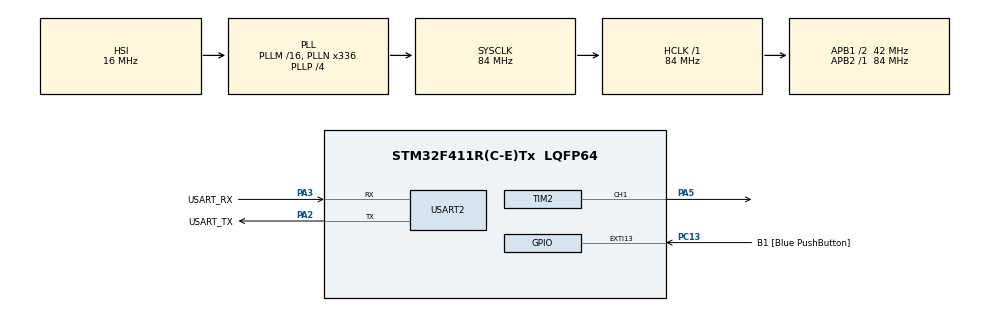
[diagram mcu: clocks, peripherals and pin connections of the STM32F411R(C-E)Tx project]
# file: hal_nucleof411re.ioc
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Mcu.Family=STM32F4
Mcu.Name=STM32F411R(C-E)Tx
Mcu.Package=LQFP64
NVIC.PriorityGroup=NVIC_PRIORITYGROUP_0
NVIC.TIM3_IRQn=true\:0\:0\:false\:false\:true\:true\:true
NVIC.TIM4_IRQn=true\:0\:0\:false\:false\:true\:true\:true
PA13.GPIO_Label=TMS
PA13.Mode=Serial_Wire
PA13.Signal=SYS_JTMS-SWDIO
PA14.GPIO_Label=TCK
PA14.Mode=Serial_Wire
PA14.Signal=SYS_JTCK-SWCLK
PA2.GPIO_Label=USART_TX
PA2.Mode=Asynchronous
PA2.Signal=USART2_TX
PA3.GPIO_Label=USART_RX
PA3.Mode=Asynchronous
PA3.Signal=USART2_RX
PA5.Signal=S_TIM2_CH1_ETR
PB3.GPIO_Label=SWO
PB3.Signal=SYS_JTDO-SWO
PC13-ANTI_TAMP.GPIO_Label=B1 [Blue PushButton]
PC13-ANTI_TAMP.GPIO_ModeDefaultEXTI=GPIO_MODE_IT_FALLING
PC13-ANTI_TAMP.Signal=GPXTI13
PC14-OSC32_IN.Mode=LSE-External-Oscillator
PC14-OSC32_IN.Signal=RCC_OSC32_IN
PC15-OSC32_OUT.Mode=LSE-External-Oscillator
PC15-OSC32_OUT.Signal=RCC_OSC32_OUT
PH0\ -\ OSC_IN.Mode=HSE-External-Clock-Source
PH0\ -\ OSC_IN.Signal=RCC_OSC_IN
PH1\ -\ OSC_OUT.Mode=HSE-External-Clock-Source
PH1\ -\ OSC_OUT.Signal=RCC_OSC_OUT
ProjectManager.HeapSize=0x200
ProjectManager.StackSize=0x400
ProjectManager.TargetToolchain=SW4STM32
RCC.48MHZClocksFreq_Value=84000000
RCC.AHBFreq_Value=84000000
RCC.APB1CLKDivider=RCC_HCLK_DIV2
RCC.APB1Freq_Value=42000000
RCC.APB1TimFreq_Value=84000000
RCC.APB2Freq_Value=84000000
RCC.APB2TimFreq_Value=84000000
RCC.CortexFreq_Value=84000000
RCC.FLatency-AdvancedSettings=FLASH_LATENCY_2
RCC.HCLKFreq_Value=84000000
RCC.HSE_VALUE=8000000
RCC.HSI_VALUE=16000000
RCC.PLLN=336
RCC.PLLP=RCC_PLLP_DIV4
RCC.SYSCLKFreq_VALUE=84000000
RCC.SYSCLKSource=RCC_SYSCLKSOURCE_PLLCLK
RCC.VCOOutputFreq_Value=336000000
SH.S_TIM2_CH1_ETR.0=TIM2_CH1,PWM Generation1 CH1
TIM2.Channel-PWM\ Generation1\ CH1=TIM_CHANNEL_1
TIM2.Period=999
TIM2.Prescaler=3
TIM3.AutoReloadPreload=TIM_AUTORELOAD_PRELOAD_ENABLE
TIM3.Period=(2333-1)/500
TIM3.Prescaler=36000-1
TIM3.TIM_MasterOutputTrigger=TIM_TRGO_UPDATE
TIM4.AutoReloadPreload=TIM_AUTORELOAD_PRELOAD_ENABLE
TIM4.Period=(2333-1)/500
TIM4.Prescaler=36000-1
TIM4.TIM_MasterOutputTrigger=TIM_TRGO_UPDATE
USART2.VirtualMode=VM_ASYNC
VP_TIM2_VS_ClockSourceINT.Mode=Internal
VP_TIM3_VS_ClockSourceINT.Mode=Internal
VP_TIM4_VS_ClockSourceINT.Mode=Internal
board=NUCLEO-F411RE

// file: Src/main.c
/* USER CODE BEGIN Header */
/**
  ******************************************************************************
  * @file           : main.c
  * @brief          : Main program body
  ******************************************************************************
  * @attention
  *
  * <h2><center>&copy; Copyright (c) 2019 STMicroelectronics.
  * All rights reserved.</center></h2>
  *
  * This software component is licensed by ST under BSD 3-Clause license,
  * the "License"; You may not use this file except in compliance with the
  * License. You may obtain a copy of the License at:
  *                        opensource.org/licenses/BSD-3-Clause
  *
  ******************************************************************************
  */
/* USER CODE END Header */

#include "main.h"

/* USER CODE BEGIN Includes */
#include "core.hpp"
/* USER CODE END Includes */

TIM_HandleTypeDef htim2;
TIM_HandleTypeDef htim3;
TIM_HandleTypeDef htim4;

UART_HandleTypeDef huart2;

/* USER CODE BEGIN PV */
#ifdef __GNUC__
#define PUTCHAR_PROTOTYPE int __io_putchar(int ch)
#else
#define PUTCHAR_PROTOTYPE int fputc(int ch, FILE *f)
#endif /* __GNUC__ */

void __io_putchar(uint8_t ch) {
    HAL_UART_Transmit(&huart2, &ch, 1, 1);
}
/* USER CODE END PV */

void SystemClock_Config(void);

static void MX_GPIO_Init(void);

static void MX_USART2_UART_Init(void);

static void MX_TIM4_Init(void);

static void MX_TIM3_Init(void);

static void MX_TIM2_Init(void);

int main(void) {

    /* MCU Configuration--------------------------------------------------------*/

    /* Reset of all peripherals, Initializes the Flash interface and the Systick. */
    HAL_Init();

    /* Configure the system clock */
    SystemClock_Config();

    /* Initialize all configured peripherals */
    MX_GPIO_Init();
    MX_USART2_UART_Init();
    MX_TIM4_Init();
    MX_TIM3_Init();
    MX_TIM2_Init();
    /* USER CODE BEGIN 2 */
    HAL_TIM_Base_Start_IT(&htim3);
    HAL_TIM_Base_Start_IT(&htim4);
    HAL_TIM_PWM_Start(&htim2, TIM_CHANNEL_1);
    /* USER CODE END 2 */

    /* Infinite loop */
    /* USER CODE BEGIN WHILE */
    Initialize(&htim2);
    Core();

    while (1) {
        /* USER CODE END WHILE */

    }
}

void SystemClock_Config(void) {
    RCC_OscInitTypeDef RCC_OscInitStruct = {0};
    RCC_ClkInitTypeDef RCC_ClkInitStruct = {0};

    /** Configure the main internal regulator output voltage
    */
    __HAL_RCC_PWR_CLK_ENABLE();
    __HAL_PWR_VOLTAGESCALING_CONFIG(PWR_REGULATOR_VOLTAGE_SCALE1);
    /** Initializes the CPU, AHB and APB busses clocks
    */
    RCC_OscInitStruct.OscillatorType = RCC_OSCILLATORTYPE_HSI;
    RCC_OscInitStruct.HSIState = RCC_HSI_ON;
    RCC_OscInitStruct.HSICalibrationValue = RCC_HSICALIBRATION_DEFAULT;
    RCC_OscInitStruct.PLL.PLLState = RCC_PLL_ON;
    RCC_OscInitStruct.PLL.PLLSource = RCC_PLLSOURCE_HSI;
    RCC_OscInitStruct.PLL.PLLM = 16;
    RCC_OscInitStruct.PLL.PLLN = 336;
    RCC_OscInitStruct.PLL.PLLP = RCC_PLLP_DIV4;
    RCC_OscInitStruct.PLL.PLLQ = 4;
    if (HAL_RCC_OscConfig(&RCC_OscInitStruct) != HAL_OK) {
        Error_Handler();
    }
    /** Initializes the CPU, AHB and APB busses clocks
    */
    RCC_ClkInitStruct.ClockType = RCC_CLOCKTYPE_HCLK | RCC_CLOCKTYPE_SYSCLK
                                  | RCC_CLOCKTYPE_PCLK1 | RCC_CLOCKTYPE_PCLK2;
    RCC_ClkInitStruct.SYSCLKSource = RCC_SYSCLKSOURCE_PLLCLK;
    RCC_ClkInitStruct.AHBCLKDivider = RCC_SYSCLK_DIV1;
    RCC_ClkInitStruct.APB1CLKDivider = RCC_HCLK_DIV2;
    RCC_ClkInitStruct.APB2CLKDivider = RCC_HCLK_DIV1;

    if (HAL_RCC_ClockConfig(&RCC_ClkInitStruct, FLASH_LATENCY_2) != HAL_OK) {
        Error_Handler();
    }
}

static void MX_TIM2_Init(void) {

    TIM_ClockConfigTypeDef sClockSourceConfig = {0};
    TIM_MasterConfigTypeDef sMasterConfig = {0};
    TIM_OC_InitTypeDef sConfigOC = {0};

    htim2.Instance = TIM2;
    htim2.Init.Prescaler = 3;
    htim2.Init.CounterMode = TIM_COUNTERMODE_UP;
    htim2.Init.Period = 999;
    htim2.Init.ClockDivision = TIM_CLOCKDIVISION_DIV1;
    htim2.Init.AutoReloadPreload = TIM_AUTORELOAD_PRELOAD_DISABLE;
    if (HAL_TIM_Base_Init(&htim2) != HAL_OK) {
        Error_Handler();
    }
    sClockSourceConfig.ClockSource = TIM_CLOCKSOURCE_INTERNAL;
    if (HAL_TIM_ConfigClockSource(&htim2, &sClockSourceConfig) != HAL_OK) {
        Error_Handler();
    }
    if (HAL_TIM_PWM_Init(&htim2) != HAL_OK) {
        Error_Handler();
    }
    sMasterConfig.MasterOutputTrigger = TIM_TRGO_RESET;
    sMasterConfig.MasterSlaveMode = TIM_MASTERSLAVEMODE_DISABLE;
    if (HAL_TIMEx_MasterConfigSynchronization(&htim2, &sMasterConfig) != HAL_OK) {
        Error_Handler();
    }
    sConfigOC.OCMode = TIM_OCMODE_PWM1;
    sConfigOC.Pulse = 0;
    sConfigOC.OCPolarity = TIM_OCPOLARITY_HIGH;
    sConfigOC.OCFastMode = TIM_OCFAST_DISABLE;
    if (HAL_TIM_PWM_ConfigChannel(&htim2, &sConfigOC, TIM_CHANNEL_1) != HAL_OK) {
        Error_Handler();
    }
    HAL_TIM_MspPostInit(&htim2);

}

static void MX_TIM3_Init(void) {

    TIM_ClockConfigTypeDef sClockSourceConfig = {0};
    TIM_MasterConfigTypeDef sMasterConfig = {0};

    htim3.Instance = TIM3;
    htim3.Init.Prescaler = 36000 - 1;
    htim3.Init.CounterMode = TIM_COUNTERMODE_UP;
    htim3.Init.Period = (2333 - 1) / 500;
    htim3.Init.ClockDivision = TIM_CLOCKDIVISION_DIV1;
    htim3.Init.AutoReloadPreload = TIM_AUTORELOAD_PRELOAD_ENABLE;
    if (HAL_TIM_Base_Init(&htim3) != HAL_OK) {
        Error_Handler();
    }
    sClockSourceConfig.ClockSource = TIM_CLOCKSOURCE_INTERNAL;
    if (HAL_TIM_ConfigClockSource(&htim3, &sClockSourceConfig) != HAL_OK) {
        Error_Handler();
    }
    sMasterConfig.MasterOutputTrigger = TIM_TRGO_UPDATE;
    sMasterConfig.MasterSlaveMode = TIM_MASTERSLAVEMODE_DISABLE;
    if (HAL_TIMEx_MasterConfigSynchronization(&htim3, &sMasterConfig) != HAL_OK) {
        Error_Handler();
    }

}

static void MX_TIM4_Init(void) {

    TIM_ClockConfigTypeDef sClockSourceConfig = {0};
    TIM_MasterConfigTypeDef sMasterConfig = {0};

    htim4.Instance = TIM4;
    htim4.Init.Prescaler = 36000 - 1;
    htim4.Init.CounterMode = TIM_COUNTERMODE_UP;
    htim4.Init.Period = (2333 - 1) / 500;
    htim4.Init.ClockDivision = TIM_CLOCKDIVISION_DIV1;
    htim4.Init.AutoReloadPreload = TIM_AUTORELOAD_PRELOAD_ENABLE;
    if (HAL_TIM_Base_Init(&htim4) != HAL_OK) {
        Error_Handler();
    }
    sClockSourceConfig.ClockSource = TIM_CLOCKSOURCE_INTERNAL;
    if (HAL_TIM_ConfigClockSource(&htim4, &sClockSourceConfig) != HAL_OK) {
        Error_Handler();
    }
    sMasterConfig.MasterOutputTrigger = TIM_TRGO_UPDATE;
    sMasterConfig.MasterSlaveMode = TIM_MASTERSLAVEMODE_DISABLE;
    if (HAL_TIMEx_MasterConfigSynchronization(&htim4, &sMasterConfig) != HAL_OK) {
        Error_Handler();
    }

}

static void MX_USART2_UART_Init(void) {

    huart2.Instance = USART2;
    huart2.Init.BaudRate = 115200;
    huart2.Init.WordLength = UART_WORDLENGTH_8B;
    huart2.Init.StopBits = UART_STOPBITS_1;
    huart2.Init.Parity = UART_PARITY_NONE;
    huart2.Init.Mode = UART_MODE_TX_RX;
    huart2.Init.HwFlowCtl = UART_HWCONTROL_NONE;
    huart2.Init.OverSampling = UART_OVERSAMPLING_16;
    if (HAL_UART_Init(&huart2) != HAL_OK) {
        Error_Handler();
    }

}

static void MX_GPIO_Init(void) {
    GPIO_InitTypeDef GPIO_InitStruct = {0};

    /* GPIO Ports Clock Enable */
    __HAL_RCC_GPIOC_CLK_ENABLE();
    __HAL_RCC_GPIOH_CLK_ENABLE();
    __HAL_RCC_GPIOA_CLK_ENABLE();
    __HAL_RCC_GPIOB_CLK_ENABLE();

    /*Configure GPIO pin : B1_Pin */
    GPIO_InitStruct.Pin = B1_Pin;
    GPIO_InitStruct.Mode = GPIO_MODE_IT_FALLING;
    GPIO_InitStruct.Pull = GPIO_NOPULL;
    HAL_GPIO_Init(B1_GPIO_Port, &GPIO_InitStruct);

}

void Error_Handler(void) {
}

/************************ (C) COPYRIGHT STMicroelectronics *****END OF FILE****/
